# Z20K14xM register map
Vendor: Zhixin Semiconductor; Series: Z20K14xM; File version: 0.1.0
CPU: CM4 r0p1, little endian, no MPU, FPU, 4 interrupt priority bits
Registers are 32-bit, read-write, reset 0x0 unless marked. A register's access mark holds for its fields unless they carry their own. Offsets are from the block's base; [hi:lo] are bit positions; {n}, {i} and the like mark numbered series.

## MCPWM0
Base 0x4000E000
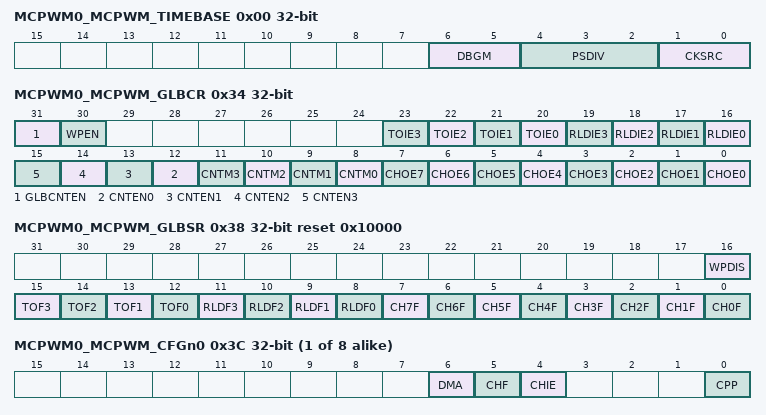
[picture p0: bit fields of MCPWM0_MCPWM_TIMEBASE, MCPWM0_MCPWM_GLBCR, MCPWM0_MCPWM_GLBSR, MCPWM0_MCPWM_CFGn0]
0x00 MCPWM0_MCPWM_TIMEBASE — MCPWM time base register
  [6:5] DBGM — Debug mode
  [4:2] PSDIV — Prescaler divider
  [1:0] CKSRC — clock source
{0x4+4i} MCPWM0_MCPWM_CNTn{i} (i=0..3) — MCPWM counter n register
  [15:0] CNT — 16-bit counter
{0x14+4i} MCPWM0_MCPWM_MODn{i} (i=0..3) — MCPWM counter n modulo value register
  [15:0] MOD — 16-bit counter modulo value
{0x24+4i} MCPWM0_MCPWM_DTVALn{i} (i=0..3) — MCPWM deadtime value n register
  [11:0] DTVAL — deadtime value
0x34 MCPWM0_MCPWM_GLBCR — MCPWM global control register
  [31] GLBCNTEN — global counter enable
  [30] WPEN — Write protection enable
  [n+20] TOIE{n} (n=0..3) — counter {n} overflow interrupt enable
  [n+16] RLDIE{n} (n=0..3) — Reload interrupt enable {n}
  [n+12] CNTEN{n} (n=0..3) — counter {n} enable
  [n+8] CNTM{n} (n=0..3) — counter {n} counting mode
  [n] CHOE{n} (n=0..7) — Channel {n} output enable
0x38 MCPWM0_MCPWM_GLBSR reset 0x10000 — MCPWM global status register
  [16] WPDIS — Write protection disable
  [n+12] TOF{n} (n=0..3) — counter {n} timer overflow flag
  [n+8] RLDF{n} (n=0..3) — counter {n} reload flag
  [n] CH{n}F (n=0..7) — Channel {n} flag
{0x3C+4i} MCPWM0_MCPWM_CFGn{i} (i=0..7) — MCPWM channel n mode configuration register
  [6] DMA — DMA enable
  [5] CHF — Channel flag
  [4] CHIE — Channel interrupt enable
  [0] CPP — channel pulse polarity
{0x5C+4i} MCPWM0_MCPWM_CVn{i} (i=0..7) — MCPWM channel n value register
  [15:0] CV — channel value
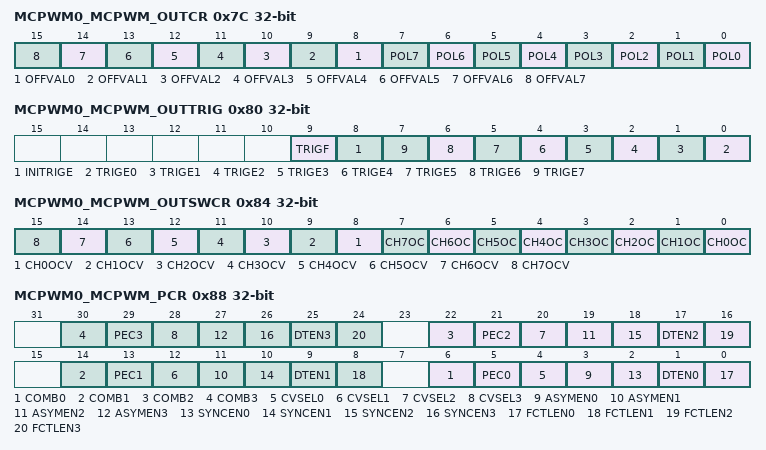
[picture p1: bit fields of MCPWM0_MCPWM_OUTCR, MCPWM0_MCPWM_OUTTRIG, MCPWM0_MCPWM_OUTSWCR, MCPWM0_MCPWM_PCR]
0x7C MCPWM0_MCPWM_OUTCR — MCPWM output control register
  [n+8] OFFVAL{n} (n=0..7) — channel {n} output value when counter is off
  [n] POL{n} (n=0..7) — Channel {n} output polarity
0x80 MCPWM0_MCPWM_OUTTRIG — MCPWM output trigger register
  [9] TRIGF — Channel output trigger flag
  [8] INITRIGE — Initialization trigger enable
  [n] TRIGE{n} (n=0..7) — Channel {n} match trigger enable
0x84 MCPWM0_MCPWM_OUTSWCR — MCPWM channel output software control register
  [n+8] CH{n}OCV (n=0..7) — Channel {n} output software control value
  [n] CH{n}OC (n=0..7) — Channel {n} output software control enable
0x88 MCPWM0_MCPWM_PCR — MCPWM pairs of channel control register
  [8n+6] COMB{n} (n=0..3) — Combine enable for pairs of channel {n}
  [8n+5] PEC{n} (n=0..3) — pulse edge control for pairs of channel {n}
  [8n+4] CVSEL{n} (n=0..3) — channel value selection of PWM output for pairs of channel {n}
  [8n+3] ASYMEN{n} (n=0..3) — asymmetric PWM output enable for pairs of channel {n}
  [8n+2] SYNCEN{n} (n=0..3) — Synchronization enable for pairs of channel {n}
  [8n+1] DTEN{n} (n=0..3) — Deadtime insertion enable for pairs of channel {n}
  [8n] FCTLEN{n} (n=0..3) — Fault control enabled for pairs of channel {n}
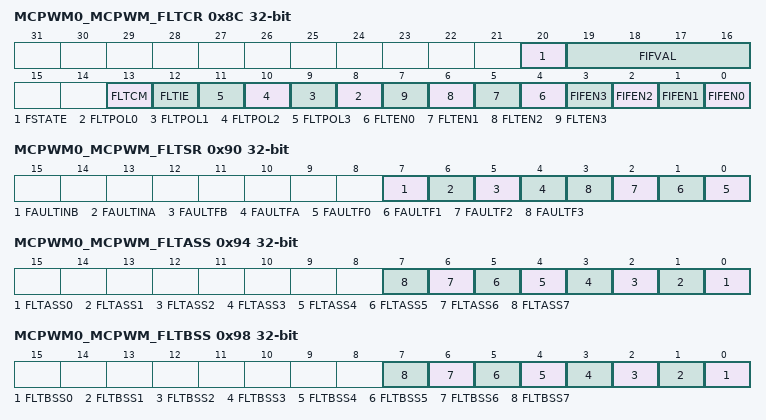
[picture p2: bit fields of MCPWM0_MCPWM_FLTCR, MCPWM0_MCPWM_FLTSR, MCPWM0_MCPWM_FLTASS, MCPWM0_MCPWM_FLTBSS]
0x8C MCPWM0_MCPWM_FLTCR — MCPWM fault control control register
  [20] FSTATE — Fault output status
  [19:16] FIFVAL — Fault input filter value
  [13] FLTCM — Falut clear mode
  [12] FLTIE — Fault interrupt enable
  [n+8] FLTPOL{n} (n=0..3) — Fault input channel {n} polarity
  [n+4] FLTEN{n} (n=0..3) — Fault input enable {n}
  [n] FIFEN{n} (n=0..3) — Fault input filter enable {n}
0x90 MCPWM0_MCPWM_FLTSR — MCPWM fault status register
  [7] FAULTINB — Fault input B value
  [6] FAULTINA — Fault input A value
  [5] FAULTFB — Fault detection flag B
  [4] FAULTFA — Fault detection flag A
  [n] FAULTF{n} (n=0..3) — Fault detection flag of fault channel {n}
0x94 MCPWM0_MCPWM_FLTASS — MCPWM fault A safe status value register
  [n] FLTASS{n} (n=0..7) — Channel {n} safe status value for fault A
0x98 MCPWM0_MCPWM_FLTBSS — MCPWM fault B safe status value register
  [n] FLTBSS{n} (n=0..7) — Channel {n} safe status value for fault B
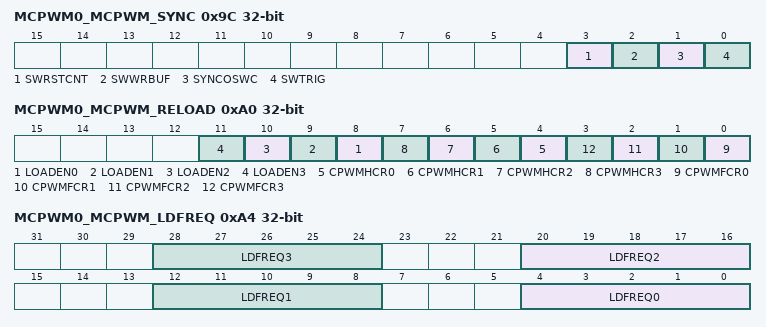
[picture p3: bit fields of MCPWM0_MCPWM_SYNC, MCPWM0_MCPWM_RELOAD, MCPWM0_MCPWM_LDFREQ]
0x9C MCPWM0_MCPWM_SYNC — MCPWM synchronization register
  [3] SWRSTCNT — Software trigger reset counter
  [2] SWWRBUF — Software trigger activate write buffer synchronization
  [1] SYNCOSWC — OUTSWCR register synchronization
  [0] SWTRIG — software trigger synchronization
0xA0 MCPWM0_MCPWM_RELOAD — MCPWM reload register
  [n+8] LOADEN{n} (n=0..3) — Reload enable for pairs of channel {n}
  [n+4] CPWMHCR{n} (n=0..3) — CPWM half cycle reload enable {n}
  [n] CPWMFCR{n} (n=0..3) — CPWM full cycle reload enable {n}
0xA4 MCPWM0_MCPWM_LDFREQ — MCPWM reload frequency register
  [8n+4:8n] LDFREQ{n} (n=0..3) — Reload frequency {n}
{0x100+4i} MCPWM0_MCPWM_MODn_DITHER{i} (i=0..3) — MCPWM MODn dither register
  [4:0] MOD_DITHER — MOD dither value
{0x110+4i} MCPWM0_MCPWM_CVn_DITHER{i} (i=0..7) — MCPWM CVn dither register
  [4:0] CV_DITHER — CV dither value

## MCPWM1
Base 0x4001A000
Registers as MCPWM0 (with MCPWM0 read as MCPWM1).
